VERSION ""

NS_ :

BS_:

BU_: RAU Display

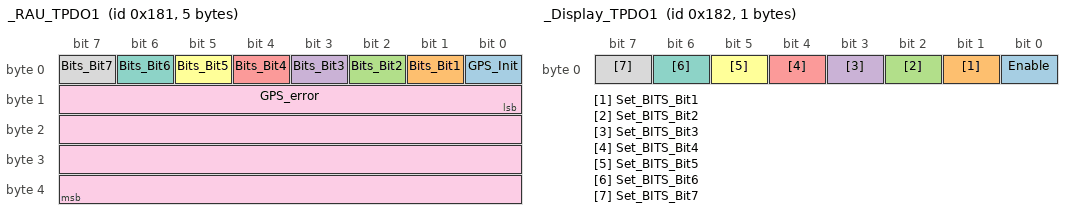
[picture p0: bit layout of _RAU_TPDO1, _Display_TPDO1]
BO_ 385 _RAU_TPDO1: 5 RAU
 SG_ GPS_Init : 0|1@1+ (1,0) [0|1] "" Display
 SG_ Bits_Bit1 : 1|1@1+ (1,0) [0|1] "" Display
 SG_ Bits_Bit2 : 2|1@1+ (1,0) [0|1] "" Display
 SG_ Bits_Bit3 : 3|1@1+ (1,0) [0|1] "" Display
 SG_ Bits_Bit4 : 4|1@1+ (1,0) [0|1] "" Display
 SG_ Bits_Bit5 : 5|1@1+ (1,0) [0|1] "" Display
 SG_ Bits_Bit6 : 6|1@1+ (1,0) [0|1] "" Display
 SG_ Bits_Bit7 : 7|1@1+ (1,0) [0|1] "" Display
 SG_ GPS_error : 8|32@1+ (1,0) [0|4294967295] "" Display

BO_ 641 _RAU_TPDO2: 8 RAU
 SG_ GPS_altitude : 0|32@1- (1,0) [-3.402823466E+38|3.402823466E+38] "" Display
 SG_ GPS_latitude : 32|32@1- (1,0) [-3.402823466E+38|3.402823466E+38] "" Display

BO_ 897 _RAU_TPDO3: 8 RAU
 SG_ GPS_longitude : 0|32@1- (1,0) [-3.402823466E+38|3.402823466E+38] "" Display
 SG_ GPS_NoOfSatellites : 32|32@1- (1,0) [-3.402823466E+38|3.402823466E+38] "" Display

BO_ 1153 _RAU_TPDO4: 8 RAU
 SG_ GPS_quality : 0|32@1- (1,0) [-3.402823466E+38|3.402823466E+38] "" Display
 SG_ GPS_speed : 32|32@1- (1,0) [-3.402823466E+38|3.402823466E+38] "" Display

BO_ 386 _Display_TPDO1: 1 Display
 SG_ Enable : 0|1@1+ (1,0) [0|1] "" RAU
 SG_ Set_BITS_Bit1 : 1|1@1+ (1,0) [0|1] "" RAU
 SG_ Set_BITS_Bit2 : 2|1@1+ (1,0) [0|1] "" RAU
 SG_ Set_BITS_Bit3 : 3|1@1+ (1,0) [0|1] "" RAU
 SG_ Set_BITS_Bit4 : 4|1@1+ (1,0) [0|1] "" RAU
 SG_ Set_BITS_Bit5 : 5|1@1+ (1,0) [0|1] "" RAU
 SG_ Set_BITS_Bit6 : 6|1@1+ (1,0) [0|1] "" RAU
 SG_ Set_BITS_Bit7 : 7|1@1+ (1,0) [0|1] "" RAU

BO_ 642 _Display_TPDO2: 8 Display
 SG_ PT100 : 0|32@1+ (1,0) [0|4294967295] "" RAU
 SG_ PT1000 : 32|32@1+ (1,0) [0|4294967295] "" RAU

CM_ SG_ 385 GPS_Init "Bit[0]";
CM_ SG_ 385 Bits_Bit1 "Bit[1]";
CM_ SG_ 385 Bits_Bit2 "Bit[2]";
CM_ SG_ 385 Bits_Bit3 "Bit[3]";
CM_ SG_ 385 Bits_Bit4 "Bit[4]";
CM_ SG_ 385 Bits_Bit5 "Bit[5]";
CM_ SG_ 385 Bits_Bit6 "Bit[6]";
CM_ SG_ 385 Bits_Bit7 "Bit[7]";
CM_ SG_ 386 Enable "Bit[0]";
CM_ SG_ 386 Set_BITS_Bit1 "Bit[1]";
CM_ SG_ 386 Set_BITS_Bit2 "Bit[2]";
CM_ SG_ 386 Set_BITS_Bit3 "Bit[3]";
CM_ SG_ 386 Set_BITS_Bit4 "Bit[4]";
CM_ SG_ 386 Set_BITS_Bit5 "Bit[5]";
CM_ SG_ 386 Set_BITS_Bit6 "Bit[6]";
CM_ SG_ 386 Set_BITS_Bit7 "Bit[7]";
BA_DEF_   "ProtocolType" STRING ;
BA_DEF_   "BusType" STRING ;
BA_DEF_ BU_  "NmJ1939IndustryGroup" INT 0 7;
BA_DEF_ BU_  "NmJ1939Function" INT 0 255;
BA_DEF_ BU_  "NmStationAddress" INT 0 255;
BA_DEF_ BU_  "NmJ1939System" INT 0 127;
BA_DEF_ BU_  "NmJ1939AAC" INT 0 1;
BA_DEF_ BO_  "VFrameFormat" ENUM "StandardCAN","ExtendedCAN","reserved","J1939PG";
BA_DEF_DEF_ "ProtocolType" "J1939";
BA_DEF_DEF_ "BusType" "CAN";
BA_DEF_DEF_ "NmJ1939IndustryGroup" 2;
BA_DEF_DEF_ "NmJ1939Function" 255;
BA_DEF_DEF_ "NmStationAddress" 128;
BA_DEF_DEF_ "NmJ1939System" 127;
BA_DEF_DEF_ "NmJ1939AAC" 1;
BA_DEF_DEF_ "VFrameFormat" "StandardCAN";
SIG_VALTYPE_ 641 GPS_altitude : 1;
SIG_VALTYPE_ 641 GPS_latitude : 1;
SIG_VALTYPE_ 897 GPS_longitude : 1;
SIG_VALTYPE_ 897 GPS_NoOfSatellites : 1;
SIG_VALTYPE_ 1153 GPS_quality : 1;
SIG_VALTYPE_ 1153 GPS_speed : 1;
